VERSION ""

NS_ :

BS_:

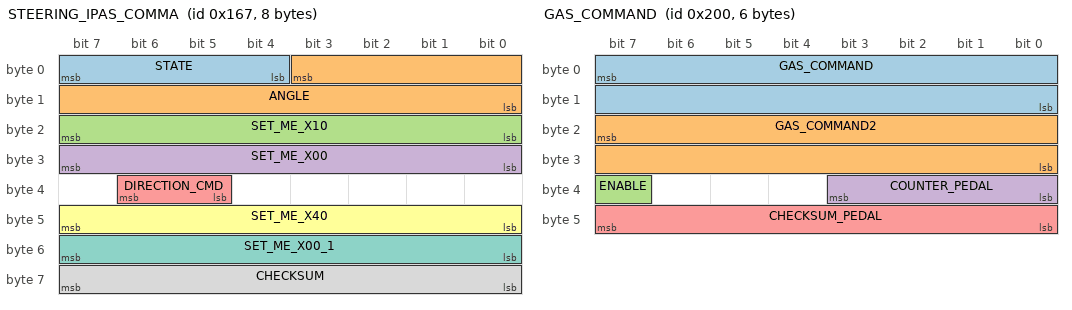
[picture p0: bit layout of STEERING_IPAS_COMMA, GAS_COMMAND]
BO_ 359 STEERING_IPAS_COMMA: 8 IPAS
 SG_ STATE : 7|4@0+ (1,0) [0|15] "" XXX
 SG_ ANGLE : 3|12@0- (1.5,0) [-510|510] "deg" XXX
 SG_ SET_ME_X10 : 23|8@0+ (1,0) [0|255] "" XXX
 SG_ SET_ME_X00 : 31|8@0+ (1,0) [0|255] "" XXX
 SG_ DIRECTION_CMD : 38|2@0+ (1,0) [0|3] "" XXX
 SG_ SET_ME_X40 : 47|8@0+ (1,0) [0|255] "" XXX
 SG_ SET_ME_X00_1 : 55|8@0+ (1,0) [0|255] "" XXX
 SG_ CHECKSUM : 63|8@0+ (1,0) [0|255] "" XXX

BO_ 512 GAS_COMMAND: 6 EON
 SG_ GAS_COMMAND : 7|16@0+ (0.159375,-75.555) [0|1] "" INTERCEPTOR
 SG_ GAS_COMMAND2 : 23|16@0+ (0.159375,-151.111) [0|1] "" INTERCEPTOR
 SG_ ENABLE : 39|1@0+ (1,0) [0|1] "" INTERCEPTOR
 SG_ COUNTER_PEDAL : 35|4@0+ (1,0) [0|15] "" INTERCEPTOR
 SG_ CHECKSUM_PEDAL : 47|8@0+ (1,0) [0|255] "" INTERCEPTOR

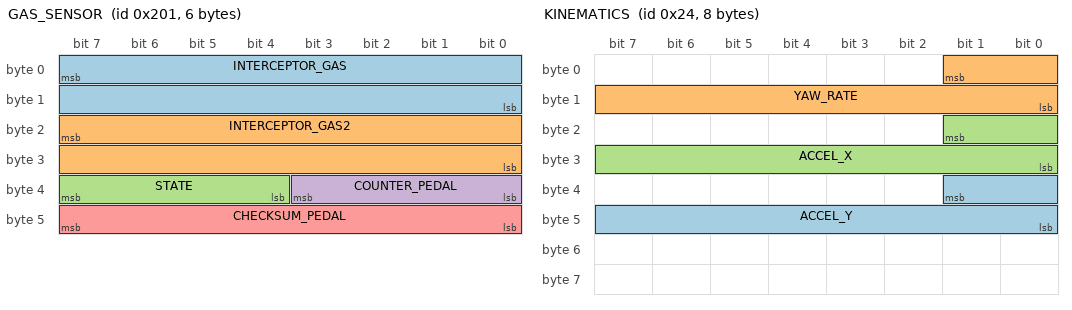
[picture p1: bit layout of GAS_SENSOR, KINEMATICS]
BO_ 513 GAS_SENSOR: 6 INTERCEPTOR
 SG_ INTERCEPTOR_GAS : 7|16@0+ (1,0) [0|1] "" EON
 SG_ INTERCEPTOR_GAS2 : 23|16@0+ (1,0) [0|1] "" EON
 SG_ STATE : 39|4@0+ (1,0) [0|15] "" EON
 SG_ COUNTER_PEDAL : 35|4@0+ (1,0) [0|15] "" EON
 SG_ CHECKSUM_PEDAL : 47|8@0+ (1,0) [0|255] "" EON

BO_ 35 SECONDARY_STEER_ANGLE: 8 XXX
 SG_ ZORRO_STEER : 7|24@0- (0.004901594652,0) [-500|500] "" XXX

BO_ 767 SDSU: 8 XXX
 SG_ FD_BUTTON : 7|1@0+ (1,0) [0|1] "" XXX

BO_ 36 KINEMATICS: 8 XXX
 SG_ ACCEL_Y : 33|10@0+ (0.03589,-18.375) [0|65535] "m/s^2" XXX
 SG_ YAW_RATE : 1|10@0+ (0.244,-125) [0|65535] "deg/s" XXX
 SG_ ACCEL_X : 17|10@0+ (0.03589,-18.375) [0|65535] "m/s^2" XXX

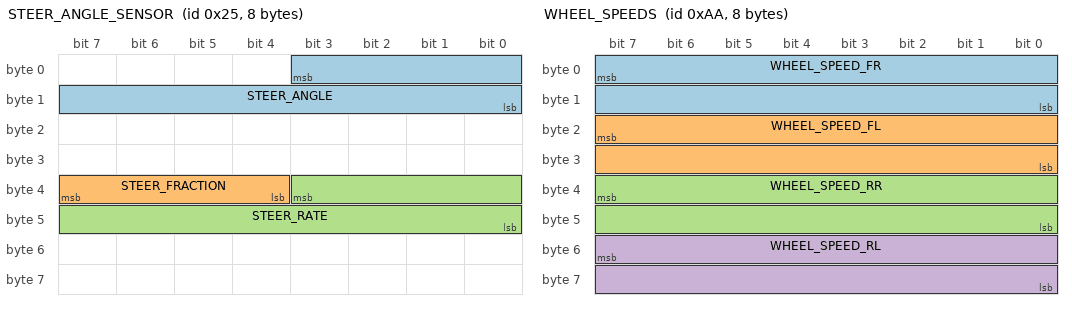
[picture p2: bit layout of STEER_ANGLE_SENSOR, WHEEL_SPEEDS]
BO_ 37 STEER_ANGLE_SENSOR: 8 XXX
 SG_ STEER_ANGLE : 3|12@0- (1.5,0) [-500|500] "deg" XXX
 SG_ STEER_FRACTION : 39|4@0- (0.1,0) [-0.7|0.7] "deg" XXX
 SG_ STEER_RATE : 35|12@0- (1,0) [-2000|2000] "deg/s" XXX

BO_ 166 BRAKE: 8 XXX
 SG_ BRAKE_AMOUNT : 7|8@0+ (1,0) [0|255] "" XXX
 SG_ BRAKE_PEDAL : 23|8@0+ (1,0) [0|255] "" XXX

BO_ 170 WHEEL_SPEEDS: 8 XXX
 SG_ WHEEL_SPEED_FR : 7|16@0+ (0.01,-67.67) [0|250] "km/h" XXX
 SG_ WHEEL_SPEED_FL : 23|16@0+ (0.01,-67.67) [0|250] "km/h" XXX
 SG_ WHEEL_SPEED_RR : 39|16@0+ (0.01,-67.67) [0|250] "km/h" XXX
 SG_ WHEEL_SPEED_RL : 55|16@0+ (0.01,-67.67) [0|250] "km/h" XXX

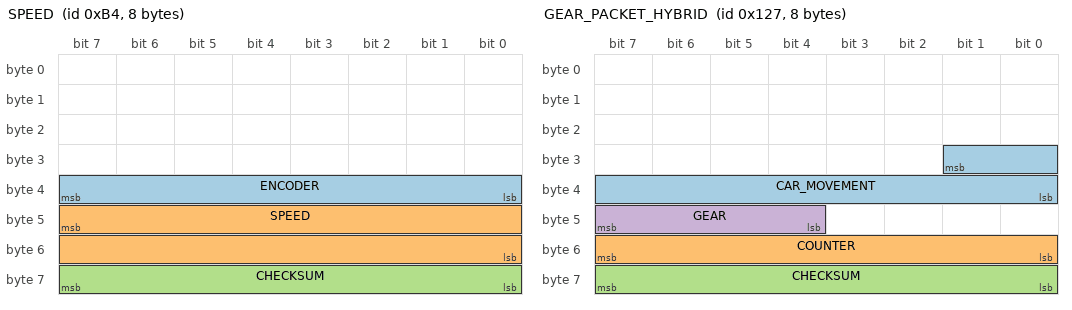
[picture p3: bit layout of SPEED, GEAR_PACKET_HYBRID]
BO_ 180 SPEED: 8 XXX
 SG_ ENCODER : 39|8@0+ (1,0) [0|255] "" XXX
 SG_ SPEED : 47|16@0+ (0.01,0) [0|250] "km/h" XXX
 SG_ CHECKSUM : 63|8@0+ (1,0) [0|255] "" XXX

BO_ 295 GEAR_PACKET_HYBRID: 8 XXX
 SG_ CAR_MOVEMENT : 25|10@0- (1,0) [0|255] "" XXX
 SG_ COUNTER : 55|8@0+ (1,0) [0|255] "" XXX
 SG_ CHECKSUM : 63|8@0+ (1,0) [0|255] "" XXX
 SG_ GEAR : 47|4@0+ (1,0) [0|15] "" XXX

BO_ 353 DSU_SPEED: 7 XXX
 SG_ FORWARD_SPEED : 15|16@0- (0.00390625,-30) [0|255] "km/h" XXX

BO_ 452 ENGINE_RPM: 8 CGW
 SG_ RPM : 7|16@0- (0.78125,0) [0|0] "rpm" SCS

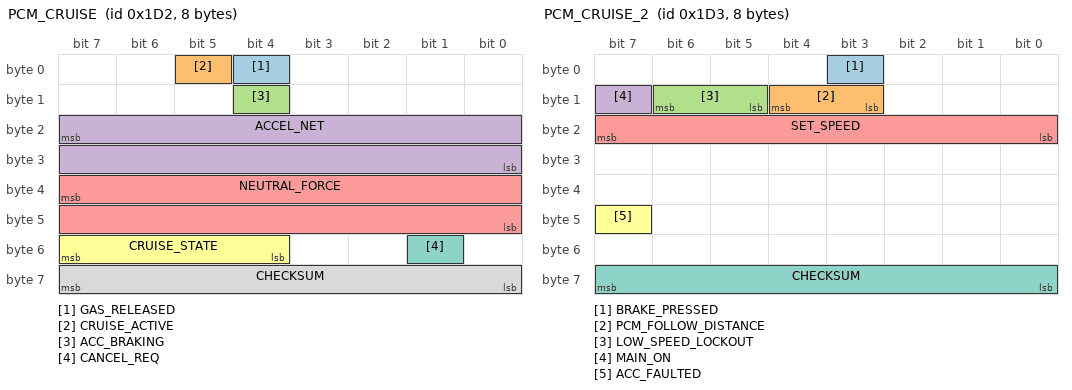
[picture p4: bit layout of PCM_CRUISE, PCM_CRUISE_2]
BO_ 466 PCM_CRUISE: 8 XXX
 SG_ GAS_RELEASED : 4|1@0+ (1,0) [0|1] "" XXX
 SG_ CRUISE_ACTIVE : 5|1@0+ (1,0) [0|1] "" XXX
 SG_ ACC_BRAKING : 12|1@0+ (1,0) [0|1] "" XXX
 SG_ ACCEL_NET : 23|16@0- (0.0009765625,0) [-20|20] "m/s^2" XXX
 SG_ NEUTRAL_FORCE : 39|16@0- (2,0) [-65536|65534] "N" XXX
 SG_ CRUISE_STATE : 55|4@0+ (1,0) [0|15] "" XXX
 SG_ CANCEL_REQ : 49|1@1+ (1,0) [0|1] "" XXX
 SG_ CHECKSUM : 63|8@0+ (1,0) [0|255] "" XXX

BO_ 467 PCM_CRUISE_2: 8 XXX
 SG_ BRAKE_PRESSED : 3|1@0+ (1,0) [0|1] "" XXX
 SG_ PCM_FOLLOW_DISTANCE : 12|2@0+ (1,0) [0|3] "" XXX
 SG_ LOW_SPEED_LOCKOUT : 14|2@0+ (1,0) [0|3] "" XXX
 SG_ MAIN_ON : 15|1@0+ (1,0) [0|1] "" XXX
 SG_ SET_SPEED : 23|8@0+ (1,0) [0|255] "km/h" XXX
 SG_ ACC_FAULTED : 47|1@0+ (1,0) [0|1] "" XXX
 SG_ CHECKSUM : 63|8@0+ (1,0) [0|255] "" XXX

BO_ 552 ACCELEROMETER: 8 XXX
 SG_ ACCEL_Z : 22|15@0- (1,0) [0|32767] "m/s^2" XXX
 SG_ ACCEL_X : 6|15@0- (0.001,0) [-20|20] "m/s^2" XXX

BO_ 560 BRAKE_2: 7 XXX
 SG_ BRAKE_PRESSED : 26|1@0+ (1,0) [0|1] "" XXX

BO_ 581 GAS_PEDAL_HYBRID: 8 XXX
 SG_ GAS_PEDAL : 23|8@0+ (0.005,0) [0|1] "" XXX

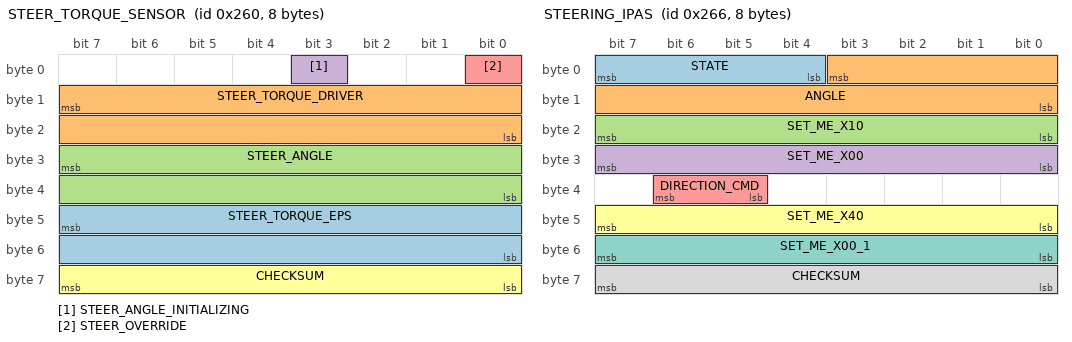
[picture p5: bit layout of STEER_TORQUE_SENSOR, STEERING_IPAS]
BO_ 608 STEER_TORQUE_SENSOR: 8 XXX
 SG_ STEER_TORQUE_EPS : 47|16@0- (1,0) [-32768|32767] "" XXX
 SG_ STEER_TORQUE_DRIVER : 15|16@0- (1,0) [-32768|32767] "" XXX
 SG_ STEER_ANGLE : 31|16@0- (0.0573,0) [-500|500] "" XXX
 SG_ STEER_ANGLE_INITIALIZING : 3|1@0+ (1,0) [0|1] "" XXX
 SG_ STEER_OVERRIDE : 0|1@0+ (1,0) [0|1] "" XXX
 SG_ CHECKSUM : 63|8@0+ (1,0) [0|255] "" XXX

BO_ 614 STEERING_IPAS: 8 IPAS
 SG_ STATE : 7|4@0+ (1,0) [0|15] "" XXX
 SG_ ANGLE : 3|12@0- (1.5,0) [-510|510] "deg" XXX
 SG_ SET_ME_X10 : 23|8@0+ (1,0) [0|255] "" XXX
 SG_ SET_ME_X00 : 31|8@0+ (1,0) [0|255] "" XXX
 SG_ DIRECTION_CMD : 38|2@0+ (1,0) [0|3] "" XXX
 SG_ SET_ME_X40 : 47|8@0+ (1,0) [0|255] "" XXX
 SG_ SET_ME_X00_1 : 55|8@0+ (1,0) [0|255] "" XXX
 SG_ CHECKSUM : 63|8@0+ (1,0) [0|255] "" XXX

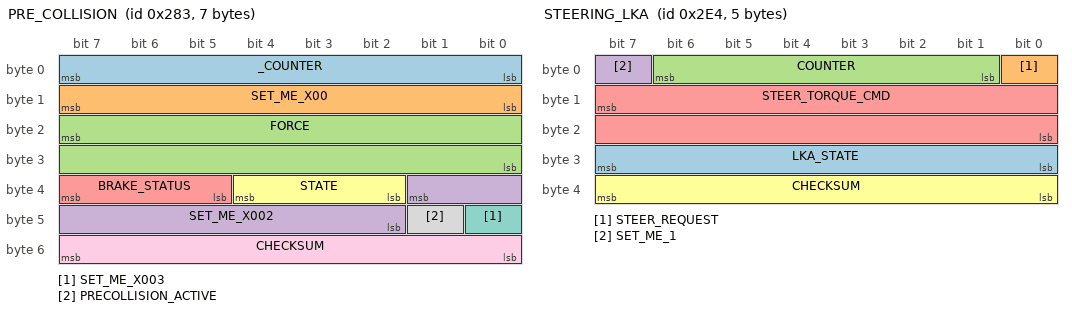
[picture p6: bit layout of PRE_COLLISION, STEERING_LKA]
BO_ 643 PRE_COLLISION: 7 DSU
 SG_ _COUNTER : 7|8@0+ (1,0) [0|255] "" XXX
 SG_ SET_ME_X00 : 15|8@0+ (1,0) [0|255] "" XXX
 SG_ FORCE : 23|16@0- (2,0) [0|255] "N" XXX
 SG_ SET_ME_X002 : 33|8@0+ (1,0) [0|3] "" XXX
 SG_ BRAKE_STATUS : 39|3@0+ (1,0) [0|255] "" XXX
 SG_ STATE : 36|3@0+ (1,0) [0|255] "" XXX
 SG_ SET_ME_X003 : 40|1@0+ (1,0) [0|1] "" XXX
 SG_ PRECOLLISION_ACTIVE : 41|1@0+ (1,0) [0|255] "" XXX
 SG_ CHECKSUM : 55|8@0+ (1,0) [0|255] "" XXX

BO_ 705 GAS_PEDAL: 8 XXX
 SG_ GAS_RELEASED : 3|1@0+ (1,0) [0|1] "" XXX
 SG_ GAS_PEDAL : 55|8@0+ (0.005,0) [0|1] "" XXX

BO_ 740 STEERING_LKA: 5 XXX
 SG_ LKA_STATE : 31|8@0+ (1,0) [0|255] "" XXX
 SG_ STEER_REQUEST : 0|1@0+ (1,0) [0|1] "" XXX
 SG_ COUNTER : 6|6@0+ (1,0) [0|63] "" XXX
 SG_ SET_ME_1 : 7|1@0+ (1,0) [0|1] "" XXX
 SG_ STEER_TORQUE_CMD : 15|16@0- (1,0) [0|65535] "" XXX
 SG_ CHECKSUM : 39|8@0+ (1,0) [0|255] "" XXX

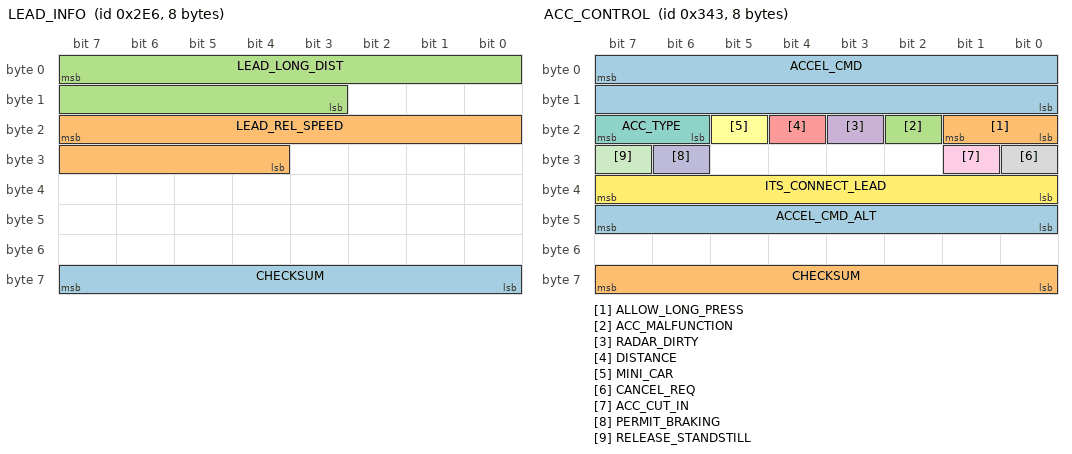
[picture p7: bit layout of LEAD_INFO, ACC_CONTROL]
BO_ 742 LEAD_INFO: 8 DSU
 SG_ CHECKSUM : 63|8@0+ (1,0) [0|255] "" HCU
 SG_ LEAD_REL_SPEED : 23|12@0- (0.025,0) [-100|100] "m/s" HCU
 SG_ LEAD_LONG_DIST : 7|13@0+ (0.05,0) [0|300] "m" HCU

BO_ 835 ACC_CONTROL: 8 DSU
 SG_ ACCEL_CMD : 7|16@0- (0.001,0) [-20|20] "m/s^2" HCU
 SG_ ALLOW_LONG_PRESS : 17|2@0+ (1,0) [0|2] "" XXX
 SG_ ACC_MALFUNCTION : 18|1@0+ (1,0) [0|0] "" XXX
 SG_ RADAR_DIRTY : 19|1@0+ (1,0) [0|1] "" XXX
 SG_ DISTANCE : 20|1@0+ (1,0) [0|1] "" XXX
 SG_ MINI_CAR : 21|1@0+ (1,0) [0|1] "" XXX
 SG_ ACC_TYPE : 23|2@0+ (1,0) [0|3] "" HCU
 SG_ CANCEL_REQ : 24|1@0+ (1,0) [0|1] "" HCU
 SG_ ACC_CUT_IN : 25|1@0+ (1,0) [0|1] "" XXX
 SG_ PERMIT_BRAKING : 30|1@0+ (1,0) [0|1] "" HCU
 SG_ RELEASE_STANDSTILL : 31|1@0+ (1,0) [0|1] "" HCU
 SG_ ITS_CONNECT_LEAD : 39|8@0+ (1,0) [0|1] "" Vector__XXX
 SG_ ACCEL_CMD_ALT : 47|8@0- (0.05,0) [0|0] "m/s^2" XXX
 SG_ CHECKSUM : 63|8@0+ (1,0) [0|255] "" XXX

BO_ 836 PRE_COLLISION_2: 8 DSU
 SG_ CHECKSUM : 63|8@0+ (1,0) [0|0] "" XXX

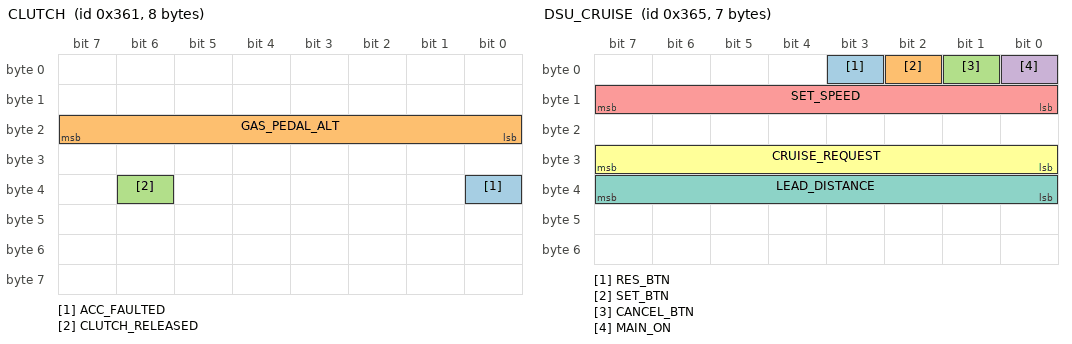
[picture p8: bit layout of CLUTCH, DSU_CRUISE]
BO_ 865 CLUTCH: 8 XXX
 SG_ ACC_FAULTED : 32|1@0+ (1,0) [0|1] "" XXX
 SG_ GAS_PEDAL_ALT : 23|8@0+ (0.005,0) [0|1] "" XXX
 SG_ CLUTCH_RELEASED : 38|1@0+ (1,0) [0|1] "" XXX

BO_ 869 DSU_CRUISE : 7 DSU
 SG_ RES_BTN : 3|1@0+ (1,0) [0|0] "" XXX
 SG_ SET_BTN : 2|1@0+ (1,0) [0|0] "" XXX
 SG_ CANCEL_BTN : 1|1@0+ (1,0) [0|0] "" XXX
 SG_ MAIN_ON : 0|1@0+ (1,0) [0|0] "" XXX
 SG_ SET_SPEED : 15|8@0+ (1,0) [0|0] "km/h" XXX
 SG_ CRUISE_REQUEST : 31|8@0+ (100,-12800) [0|0] "N" XXX
 SG_ LEAD_DISTANCE : 39|8@0+ (1,0) [0|0] "m" XXX

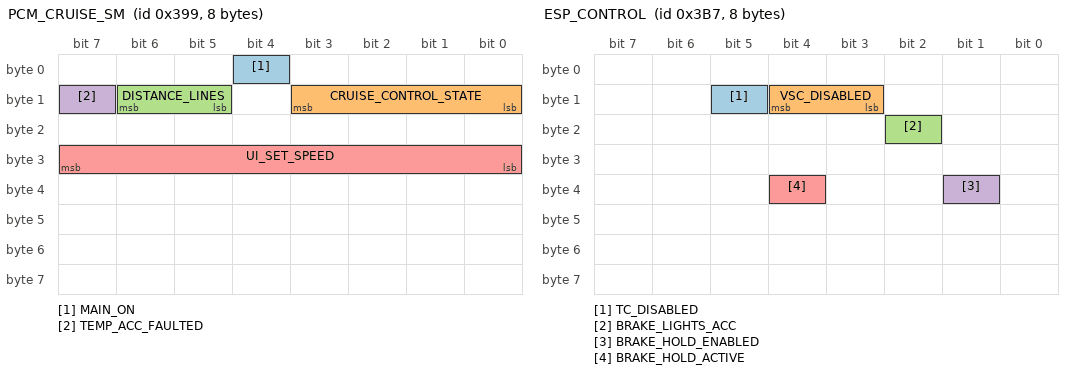
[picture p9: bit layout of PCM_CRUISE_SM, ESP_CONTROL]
BO_ 921 PCM_CRUISE_SM: 8 XXX
 SG_ MAIN_ON : 4|1@0+ (1,0) [0|1] "" XXX
 SG_ CRUISE_CONTROL_STATE : 11|4@0+ (1,0) [0|15] "" XXX
 SG_ DISTANCE_LINES : 14|2@0+ (1,0) [0|3] "" XXX
 SG_ TEMP_ACC_FAULTED : 15|1@0+ (1,0) [0|1] "" XXX
 SG_ UI_SET_SPEED : 31|8@0+ (1,0) [0|255] "" XXX

BO_ 951 ESP_CONTROL: 8 ESP
 SG_ TC_DISABLED : 13|1@0+ (1,0) [0|1] "" XXX
 SG_ VSC_DISABLED : 12|2@0+ (1,0) [0|1] "" XXX
 SG_ BRAKE_LIGHTS_ACC : 18|1@0+ (1,0) [0|1] "" XXX
 SG_ BRAKE_HOLD_ENABLED : 33|1@1+ (1,0) [0|1] "" XXX
 SG_ BRAKE_HOLD_ACTIVE : 36|1@0+ (1,0) [0|1] "" XXX

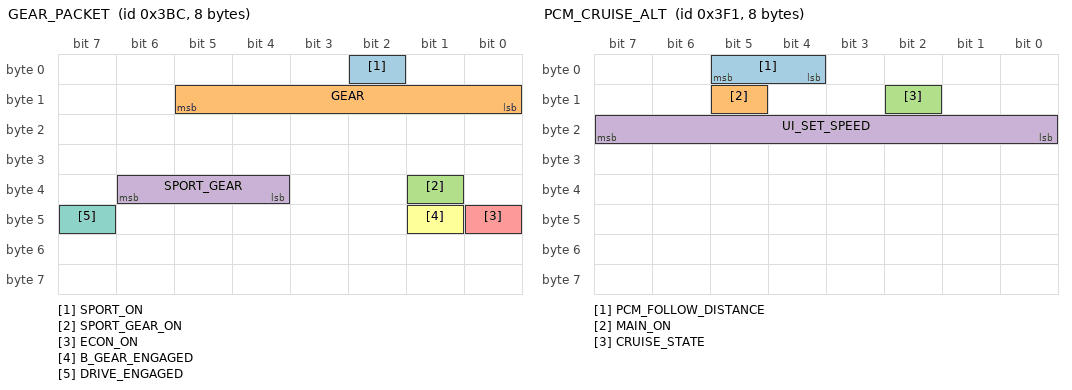
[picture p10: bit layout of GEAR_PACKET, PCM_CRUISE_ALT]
BO_ 956 GEAR_PACKET: 8 XXX
 SG_ SPORT_ON : 2|1@0+ (1,0) [0|1] "" XXX
 SG_ GEAR : 13|6@0+ (1,0) [0|63] "" XXX
 SG_ SPORT_GEAR_ON : 33|1@0+ (1,0) [0|1] "" XXX
 SG_ SPORT_GEAR : 38|3@0+ (1,0) [0|7] "" XXX
 SG_ ECON_ON : 40|1@0+ (1,0) [0|1] "" XXX
 SG_ B_GEAR_ENGAGED : 41|1@0+ (1,0) [0|1] "" XXX
 SG_ DRIVE_ENGAGED : 47|1@0+ (1,0) [0|1] "" XXX

BO_ 1005 REVERSE_CAMERA_STATE: 2 BGM
 SG_ REVERSE_CAMERA_GUIDELINES : 9|2@0+ (1,0) [1|3] "" XXX

BO_ 1009 PCM_CRUISE_ALT: 8 XXX
 SG_ PCM_FOLLOW_DISTANCE : 4|2@1+ (1,0) [0|3] "" XXX
 SG_ MAIN_ON : 13|1@0+ (1,0) [0|3] "" XXX
 SG_ CRUISE_STATE : 10|1@0+ (1,0) [0|1] "" XXX
 SG_ UI_SET_SPEED : 23|8@0+ (1,0) [0|255] "mph" XXX

BO_ 1020 SOLAR_SENSOR: 8 XXX
 SG_ LUX_SENSOR : 55|13@0+ (1,0) [0|0] "" XXX

BO_ 1041 PCS_HUD: 8 DSU
 SG_ PCS_INDICATOR : 7|2@0+ (1,0) [0|3] "" XXX
 SG_ FCW : 4|1@0+ (1,0) [0|1] "" XXX
 SG_ SET_ME_X20 : 15|8@0+ (1,0) [0|1] "" XXX
 SG_ PCS_DUST : 34|1@0+ (1,0) [0|0] "" XXX
 SG_ PCS_TEMP : 35|1@0+ (1,0) [0|0] "" XXX
 SG_ PCS_DUST2 : 41|1@0+ (1,0) [0|0] "" XXX
 SG_ PCS_TEMP2 : 42|1@0+ (1,0) [0|0] "" XXX
 SG_ SET_ME_X10 : 39|8@0+ (1,0) [0|1] "" XXX
 SG_ PCS_OFF : 40|1@0+ (1,0) [0|0] "" XXX
 SG_ FRD_ADJ : 53|3@0+ (1,0) [0|0] "" XXX
 SG_ PCS_SENSITIVITY : 55|8@0+ (1,0) [0|1] "" XXX

BO_ 1042 LKAS_HUD: 8 DSU
 SG_ BARRIERS : 1|2@0+ (1,0) [0|3] "" XXX
 SG_ RIGHT_LINE : 3|2@0+ (1,0) [0|3] "" XXX
 SG_ LEFT_LINE : 5|2@0+ (1,0) [0|3] "" XXX
 SG_ LKAS_STATUS : 7|2@0+ (1,0) [0|3] "" XXX
 SG_ LDA_ALERT : 9|2@0+ (1,0) [0|3] "" XXX
 SG_ LDW_EXIST : 10|1@0+ (1,0) [0|1] "" XXX
 SG_ TWO_BEEPS : 12|1@0+ (1,0) [0|1] "" XXX
 SG_ ADJUSTING_CAMERA : 13|1@0+ (1,0) [0|1] "" XXX
 SG_ LDA_UNAVAILABLE_QUIET : 14|1@0+ (1,0) [0|1] "" XXX
 SG_ LDA_MALFUNCTION : 15|1@0+ (1,0) [0|1] "" XXX
 SG_ LDA_UNAVAILABLE : 16|1@0+ (1,0) [0|1] "" XXX
 SG_ LDA_SENSITIVITY : 18|2@0+ (1,0) [0|3] "" XXX
 SG_ LDA_SA_TOGGLE : 20|2@0+ (1,0) [0|3] "" XXX
 SG_ LDA_MESSAGES : 23|3@0+ (1,0) [0|1] "" XXX
 SG_ LDA_ON_MESSAGE : 31|2@0+ (1,0) [0|3] "" XXX
 SG_ REPEATED_BEEPS : 32|1@0+ (1,0) [0|1] "" XXX
 SG_ LANE_SWAY_TOGGLE : 43|1@0+ (1,0) [0|1] "" XXX
 SG_ LANE_SWAY_SENSITIVITY : 45|2@0+ (1,0) [0|3] "" XXX
 SG_ TAKE_CONTROL : 46|1@0+ (1,0) [0|1] "" XXX
 SG_ LDA_FRONT_CAMERA_BLOCKED : 47|1@0+ (1,0) [0|1] "" XXX
 SG_ LANE_SWAY_BUZZER : 50|2@0+ (1,0) [0|0] "" XXX
 SG_ LANE_SWAY_FLD : 53|3@0+ (1,0) [0|7] "" XXX
 SG_ LANE_SWAY_WARNING : 55|2@0+ (1,0) [0|3] "" XXX
 SG_ SET_ME_X01 : 42|1@0+ (1,0) [0|1] "" XXX
 SG_ SET_ME_X02 : 63|8@0+ (1,0) [0|1] "" XXX

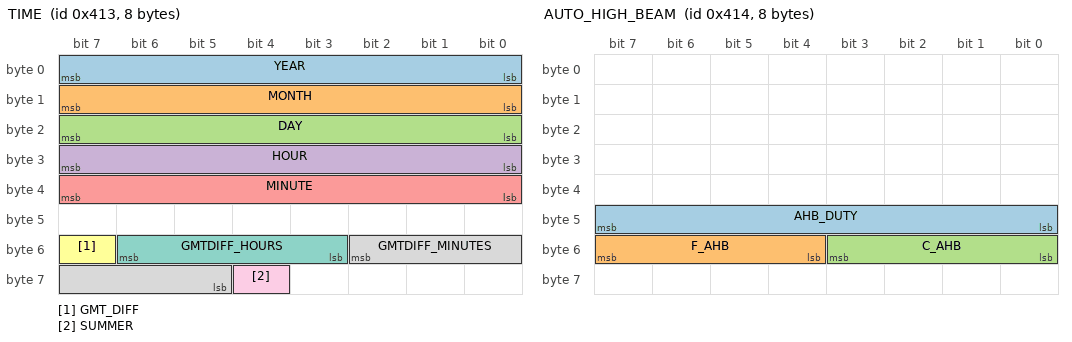
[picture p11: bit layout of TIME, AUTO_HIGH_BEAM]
BO_ 1043 TIME : 8 CGW
 SG_ YEAR : 7|8@0+ (1,0) [0|0] "year" XXX
 SG_ MONTH : 15|8@0+ (1,0) [0|0] "month" XXX
 SG_ DAY : 23|8@0+ (1,0) [0|0] "day" XXX
 SG_ HOUR : 31|8@0+ (1,0) [0|0] "hour" XXX
 SG_ MINUTE : 39|8@0+ (1,0) [0|0] "minute" XXX
 SG_ GMT_DIFF : 55|1@0+ (1,0) [0|0] "" XXX
 SG_ GMTDIFF_HOURS : 54|4@0+ (1,0) [0|0] "hours" XXX
 SG_ GMTDIFF_MINUTES : 50|6@0+ (1,0) [0|0] "minutes" XXX
 SG_ SUMMER : 60|1@0+ (1,0) [0|0] "" XXX

BO_ 1044 AUTO_HIGH_BEAM: 8 FCM
 SG_ AHB_DUTY : 47|8@0+ (0.5,0) [0|0] "%" Vector__XXX
 SG_ F_AHB : 55|4@0+ (1,0) [0|0] "" Vector__XXX
 SG_ C_AHB : 51|4@0+ (1,0) [0|0] "" Vector__XXX

BO_ 1083 AUTOPARK_STATUS: 8 IPAS
 SG_ STATE : 7|4@0+ (1,0) [0|15] "" XXX

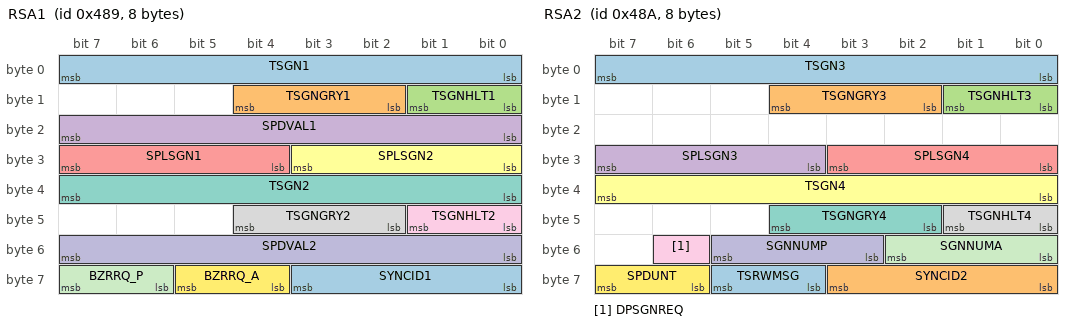
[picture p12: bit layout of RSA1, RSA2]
BO_ 1161 RSA1: 8 FCM
 SG_ TSGN1 : 7|8@0+ (1,0) [0|0] "" XXX
 SG_ TSGNGRY1 : 12|3@0+ (1,0) [0|0] "" XXX
 SG_ TSGNHLT1 : 9|2@0+ (1,0) [0|0] "" XXX
 SG_ SPDVAL1 : 23|8@0+ (1,0) [0|0] "km/h" XXX
 SG_ SPLSGN1 : 31|4@0+ (1,0) [0|0] "" XXX
 SG_ SPLSGN2 : 27|4@0+ (1,0) [0|0] "" XXX
 SG_ TSGN2 : 39|8@0+ (1,0) [0|0] "" XXX
 SG_ TSGNGRY2 : 44|3@0+ (1,0) [0|0] "" XXX
 SG_ TSGNHLT2 : 41|2@0+ (1,0) [0|0] "" XXX
 SG_ SPDVAL2 : 55|8@0+ (1,0) [0|0] "" XXX
 SG_ BZRRQ_P : 63|2@0+ (1,0) [0|0] "" XXX
 SG_ BZRRQ_A : 61|2@0+ (1,0) [0|0] "" XXX
 SG_ SYNCID1 : 59|4@0+ (1,0) [0|0] "" XXX

BO_ 1162 RSA2: 8 FCM
 SG_ TSGN3 : 7|8@0+ (1,0) [0|0] "" XXX
 SG_ TSGNGRY3 : 12|3@0+ (1,0) [0|0] "" XXX
 SG_ TSGNHLT3 : 9|2@0+ (1,0) [0|0] "" XXX
 SG_ SPLSGN3 : 31|4@0+ (1,0) [0|0] "" XXX
 SG_ SPLSGN4 : 27|4@0+ (1,0) [0|0] "" XXX
 SG_ TSGN4 : 39|8@0+ (1,0) [0|0] "" XXX
 SG_ TSGNGRY4 : 44|3@0+ (1,0) [0|0] "" XXX
 SG_ TSGNHLT4 : 41|2@0+ (1,0) [0|0] "" XXX
 SG_ DPSGNREQ : 54|1@0+ (1,0) [0|0] "" XXX
 SG_ SGNNUMP : 53|3@0+ (1,0) [0|0] "" XXX
 SG_ SGNNUMA : 50|3@0+ (1,0) [0|0] "" XXX
 SG_ SPDUNT : 63|2@0+ (1,0) [0|0] "" XXX
 SG_ TSRWMSG : 61|2@0+ (1,0) [0|0] "" XXX
 SG_ SYNCID2 : 59|4@0+ (1,0) [0|0] "" XXX

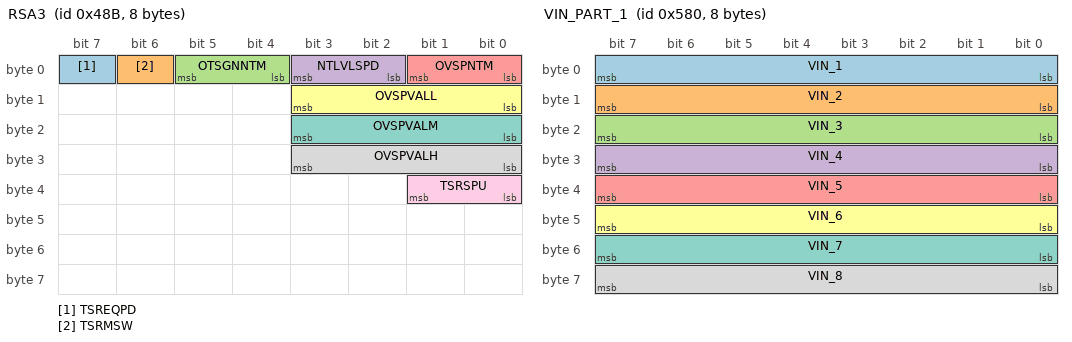
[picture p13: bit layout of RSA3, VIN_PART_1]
BO_ 1163 RSA3: 8 FCM
 SG_ TSREQPD : 7|1@0+ (1,0) [0|0] "" XXX
 SG_ TSRMSW : 6|1@0+ (1,0) [0|0] "" XXX
 SG_ OTSGNNTM : 5|2@0+ (1,0) [0|0] "" XXX
 SG_ NTLVLSPD : 3|2@0+ (1,0) [0|0] "" XXX
 SG_ OVSPNTM : 1|2@0+ (1,0) [0|0] "" XXX
 SG_ OVSPVALL : 11|4@0+ (1,-5) [0|0] "" XXX
 SG_ OVSPVALM : 19|4@0+ (1,-5) [0|0] "" XXX
 SG_ OVSPVALH : 27|4@0+ (1,-5) [0|0] "" XXX
 SG_ TSRSPU : 33|2@0+ (1,0) [0|0] "" XXX

BO_ 1408 VIN_PART_1: 8 CGW
 SG_ VIN_1 : 7|8@0+ (1,0) [0|0] "" XXX
 SG_ VIN_2 : 15|8@0+ (1,0) [0|0] "" XXX
 SG_ VIN_3 : 23|8@0+ (1,0) [0|0] "" XXX
 SG_ VIN_4 : 31|8@0+ (1,0) [0|0] "" XXX
 SG_ VIN_5 : 39|8@0+ (1,0) [0|0] "" XXX
 SG_ VIN_6 : 47|8@0+ (1,0) [0|0] "" XXX
 SG_ VIN_7 : 55|8@0+ (1,0) [0|0] "" XXX
 SG_ VIN_8 : 63|8@0+ (1,0) [0|0] "" XXX

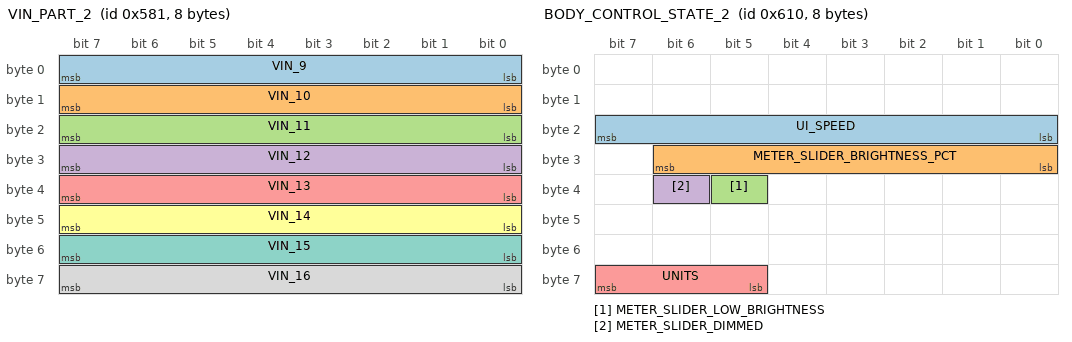
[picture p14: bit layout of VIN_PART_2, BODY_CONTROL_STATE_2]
BO_ 1409 VIN_PART_2: 8 CGW
 SG_ VIN_9 : 7|8@0+ (1,0) [0|0] "" XXX
 SG_ VIN_10 : 15|8@0+ (1,0) [0|0] "" XXX
 SG_ VIN_11 : 23|8@0+ (1,0) [0|0] "" XXX
 SG_ VIN_12 : 31|8@0+ (1,0) [0|0] "" XXX
 SG_ VIN_13 : 39|8@0+ (1,0) [0|0] "" XXX
 SG_ VIN_14 : 47|8@0+ (1,0) [0|0] "" XXX
 SG_ VIN_15 : 55|8@0+ (1,0) [0|0] "" XXX
 SG_ VIN_16 : 63|8@0+ (1,0) [0|0] "" XXX

BO_ 1410 VIN_PART_3: 8 CGW
 SG_ VIN_17 : 7|8@0+ (1,0) [0|0] "" XXX

BO_ 1552 BODY_CONTROL_STATE_2: 8 XXX
 SG_ UI_SPEED : 23|8@0+ (1,0) [0|255] "" XXX
 SG_ METER_SLIDER_BRIGHTNESS_PCT : 30|7@0+ (1,0) [12|100] "%" XXX
 SG_ METER_SLIDER_LOW_BRIGHTNESS : 37|1@0+ (1,0) [0|1] "" XXX
 SG_ METER_SLIDER_DIMMED : 38|1@0+ (1,0) [0|1] "" XXX
 SG_ UNITS : 63|3@0+ (1,0) [1|4] "" XXX

BO_ 1553 UI_SETTING: 8 XXX
 SG_ UNITS : 26|2@0+ (1,0) [0|3] "" XXX
 SG_ ODOMETER : 39|32@0+ (1,0) [0|1048575] "" XXX
BO_ 1556 BLINKERS_STATE: 8 XXX
 SG_ TURN_SIGNALS : 29|2@0+ (1,0) [0|3] "" XXX
 SG_ HAZARD_LIGHT : 27|1@0+ (1,0) [0|1] "" XXX

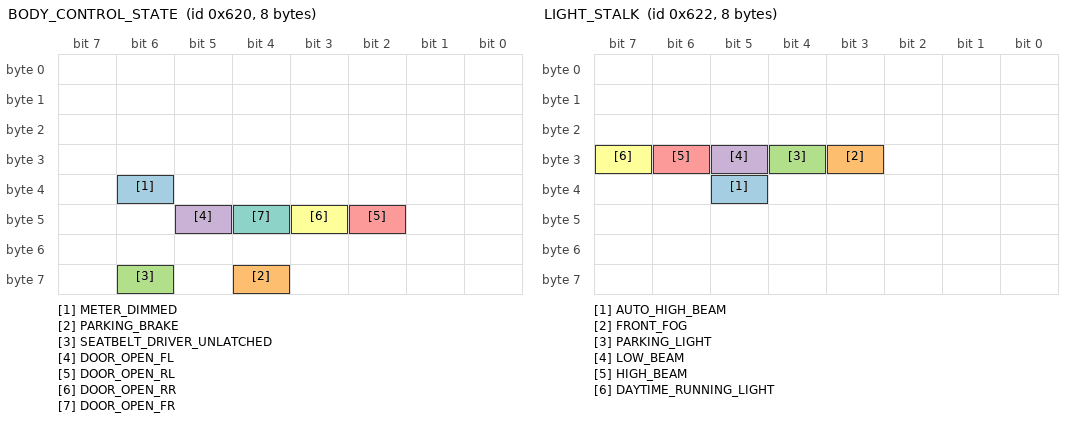
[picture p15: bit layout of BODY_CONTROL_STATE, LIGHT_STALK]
BO_ 1568 BODY_CONTROL_STATE: 8 XXX
 SG_ METER_DIMMED : 38|1@0+ (1,0) [0|1] "" XXX
 SG_ PARKING_BRAKE : 60|1@0+ (1,0) [0|1] "" XXX
 SG_ SEATBELT_DRIVER_UNLATCHED : 62|1@0+ (1,0) [0|1] "" XXX
 SG_ DOOR_OPEN_FL : 45|1@0+ (1,0) [0|1] "" XXX
 SG_ DOOR_OPEN_RL : 42|1@0+ (1,0) [0|1] "" XXX
 SG_ DOOR_OPEN_RR : 43|1@0+ (1,0) [0|1] "" XXX
 SG_ DOOR_OPEN_FR : 44|1@0+ (1,0) [0|1] "" XXX

BO_ 1570 LIGHT_STALK: 8 SCM
 SG_ AUTO_HIGH_BEAM : 37|1@0+ (1,0) [0|1] "" XXX
 SG_ FRONT_FOG : 27|1@0+ (1,0) [0|1] "" XXX
 SG_ PARKING_LIGHT : 28|1@0+ (1,0) [0|1] "" XXX
 SG_ LOW_BEAM : 29|1@0+ (1,0) [0|1] "" XXX
 SG_ HIGH_BEAM : 30|1@0+ (1,0) [0|1] "" XXX
 SG_ DAYTIME_RUNNING_LIGHT : 31|1@0+ (1,0) [0|1] "" XXX

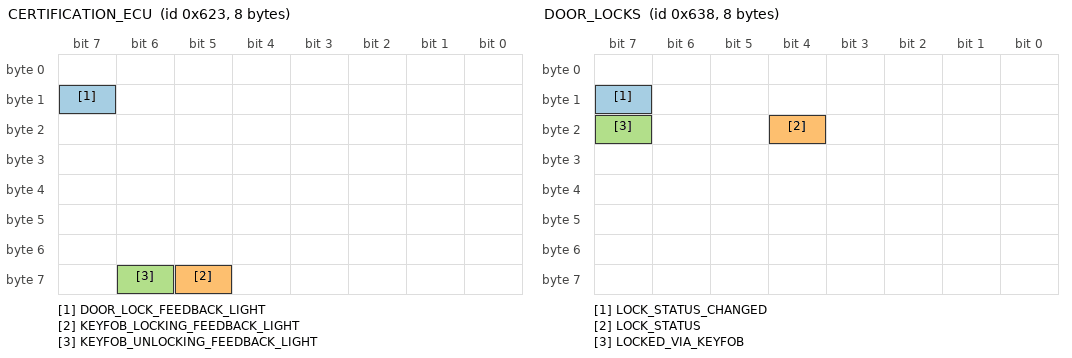
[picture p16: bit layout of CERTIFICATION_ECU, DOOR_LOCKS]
BO_ 1571 CERTIFICATION_ECU: 8 CGW
 SG_ DOOR_LOCK_FEEDBACK_LIGHT : 15|1@0+ (1,0) [0|0] "" XXX
 SG_ KEYFOB_LOCKING_FEEDBACK_LIGHT : 61|1@0+ (1,0) [0|0] "" XXX
 SG_ KEYFOB_UNLOCKING_FEEDBACK_LIGHT : 62|1@0+ (1,0) [0|0] "" XXX

BO_ 1592 DOOR_LOCKS: 8 XXX
 SG_ LOCK_STATUS_CHANGED : 15|1@0+ (1,0) [0|1] "" XXX
 SG_ LOCK_STATUS : 20|1@0+ (1,0) [0|1] "" XXX
 SG_ LOCKED_VIA_KEYFOB : 23|1@0+ (1,0) [0|1] "" XXX

BO_ 548 BRAKE_MODULE: 8 XXX
 SG_ BRAKE_PRESSURE : 43|12@0+ (1,0) [0|4047] "" XXX
 SG_ BRAKE_PRESSED : 5|1@0+ (1,0) [0|1] "" XXX

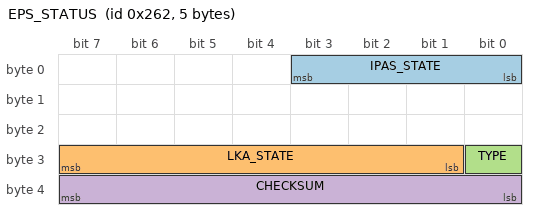
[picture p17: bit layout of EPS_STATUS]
BO_ 610 EPS_STATUS: 5 EPS
 SG_ IPAS_STATE : 3|4@0+ (1,0) [0|15] "" XXX
 SG_ LKA_STATE : 31|7@0+ (1,0) [0|127] "" XXX
 SG_ TYPE : 24|1@0+ (1,0) [0|1] "" XXX
 SG_ CHECKSUM : 39|8@0+ (1,0) [0|255] "" XXX

BO_ 1178 BRAKE_RELATED: 8 XXX
 SG_ BRAKE_PRESSED : 48|1@0+ (1,0) [0|1] "" XXX

BU_: RRSRR_FO LRSRR_FO CIPM_FO _DOFIMU2_FO _DOFIMU1_FO DMS_FO AMM_FO EOCM2B_IMX6_FO EOCM2B_K2_FO EOCM2B_K1_FO EOCM2A_IMX6_FO EOCM2A_K2_FO EOCM2A_K1_FO NVS_FO Dummy_FO TestTool_FO LRR_FO RFSRR_FO LFSRR_FO RSRR_FO VIS_FO EOCM_F_FO VIS2_FO
VAL_TABLE_ vt_BooleanValues 1 "true" 0 "false" ;
VAL_TABLE_ FrntVsnInPthVehBrkNwSt 10 "Active" 5 "Inactive" ;
VAL_TABLE_ FrntVsnClostPedBrkNwSt 10 "Active" 5 "Inactive" ;
VAL_TABLE_ DrvrMonSysEngSt 7 "Unused and Reserved 1" 6 "Recovering" 5 "Tracking" 4 "Searching" 3 "Video test port only" 2 "Idle" 1 "Invalid state" 0 "Does not exist or DME" ;
VAL_TABLE_ DrvrMonEngUnrecvrFltCod 7 "Unused and Reserved 3" 6 "Unused and Reserved 2" 5 "Unused and Reserved 1" 4 "Vehicle power supply Errors" 3 "Problem with LED illuminators" 2 "Vehicle input signals Errors" 1 "Problem with imager" 0 "Ok" ;
VAL_TABLE_ DrvrMonEngRecvrFltCod 3 "Engine is unable to find a face" 2 "Input Images too dark" 1 "Input images too bright" 0 "Ok" ;
VAL_TABLE_ DrvrMntrSysVTP 1 "Video test port active" 0 "Video test port inactive" ;
VAL_TABLE_ DrvrAttnStatCnfdc 3 "High" 2 "Medium" 1 "Low" 0 "Lowest" ;
VAL_TABLE_ DrvrAttnStat 7 "Invalid" 6 "Driver is exhibiting sleep" 5 "Driver is exhibiting microsleep" 4 "Attention is Center Console" 3 "Attention is Drivers Lap" 2 "Attention is Off Road" 1 "Attention is On Road" 0 "Unknown" ;
VAL_TABLE_ PPSMd 7 "GNSS and RTX and DR and MM" 6 "DR ONLY" 5 "GNSS and RTX and DR" 4 "GNSS and SBAS and DR" 3 "GNSS and DR" 2 "GNSS and  RTX" 1 "GNSS and SBAS" 0 "GNSS Standalone" ;
VAL_TABLE_ AdvDrvAstMpPrfShrtAcur 3 "Accuracy Is Unknown" 2 "Lowest Accuracy" 1 "Medium Accuracy" 0 "Highest Accuracy" ;
VAL_TABLE_ AdvDrAstMpStbRtOfWay 3 "Not Applicable" 2 "Unknown" 1 "Sub Path Has Right Of Way Over Path" 0 "Path Has Right Of Way Over Sub Path" ;
VAL_TABLE_ AdvDrAstMpStbPrtCalRut 3 "Not Applicable" 2 "Unknown" 1 "Path From This Point On Is Part Of Calculated Route" 0 "Path From This Point On Is Not Part Of Calculated Route" ;
VAL_TABLE_ AdvDrAstMpStbMsgTyp 7 "Unused and Reserved 2" 6 "Metadata" 5 "Profile Long" 4 "Profile Short" 3 "Stub" 2 "Segment" 1 "Position" 0 "Unused and Reserved 1" ;
VAL_TABLE_ AdvDrAstMpStbFmOfWay 15 "Not Applicable" 14 "Pedestrian Zone" 13 "Entrance To Or Exit To Service" 12 "Entrance To Or Exit Of A Car Park" 11 "Service Road Or Frontage Road" 10 "Slip Road per Ramp" 9 "Slip Road per Ramp On A Freeway Or Controlled Access Road" 8 "Parallel Road" 7 "Unused and Reserved 2" 6 "Unused and Reserved 1" 5 "Traffic Square per Special Traffic Figure" 4 "Roundabout Circle" 3 "Single Carriageway" 2 "Multiple Carriageway Or Multiply Digitized Road" 1 "Freeway Or Controlled Access Road That Is Not A Slip Road Or Ramp" 0 "Unknown" ;
VAL_TABLE_ AdvDrAstMpStbCmplxInsct 3 "Not Applicable" 2 "Unknown" 1 "Stub Is Part Of Complex Intersection" 0 "Stub Is Not Part Of Complex Intersection" ;
VAL_TABLE_ AdvDrAstMpSegTunl 3 "Not Applicable" 2 "Unknown" 1 "Segment Is Part Of Tunnel" 0 "Segment Is Not A Part Of Tunnel" ;
VAL_TABLE_ AdvDrAstMpSegPrtCalRut 3 "Not Applicable" 2 "Unknown" 1 "Segment Is Part Of Calculated Route" 0 "Segment Is Not Part Of Calculated Route" ;
VAL_TABLE_ AdvDrAstMpSegMsgTyp 7 "Unused and Reserved 2" 6 "Metadata" 5 "Profile Long" 4 "Profile Short" 3 "Stub" 2 "Segment" 1 "Position" 0 "Unused and Reserved 1" ;
VAL_TABLE_ AdvDrAstMpSegFrmOfWay 15 "Not Applicable" 14 "Pedestrian Zone" 13 "Entrance To Or Exit To Service" 12 "Entrance To Or Exit Of A Car Park" 11 "Service Road Or Frontage Road" 10 "Slip Road per Ramp" 9 "Slip Road per Ramp On A Freeway Or Controlled Access Road" 8 "Parallel Road" 7 "Unused and Reserved 2" 6 "Unused and Reserved 1" 5 "Traffic Square per Special Traffic Figure" 4 "Roundabout Circle" 3 "Single Carriageway" 2 "Multiple Carriageway Or Multiply Digitized Road" 1 "Freeway Or Controlled Access Road That Is Not A Slip Road or Ramp" 0 "Unknown" ;
VAL_TABLE_ AdvDrAstMpSegEffSdLmtTp 7 "Not Applicable" 6 "Explicit Snow" 5 "Explicit Rain" 4 "Explicit Time Of Day" 3 "Explicit By Day" 2 "Explicit By Night" 1 "Explicit On Traffic Sign" 0 "Implicit" ;
VAL_TABLE_ AdvDrAstMpSegDivdRd 3 "Not Applicable" 2 "Unknown" 1 "Segment Is Part Of Divided Road" 0 "Segment Is Not Part Of Divided Road" ;
VAL_TABLE_ AdvDrAstMpSegCmplxInsct 3 "Not Applicable" 2 "Unknown" 1 "Segment Is Part Of Complex Intersection" 0 "Segment Is Not Part Of Complex Intersection" ;
VAL_TABLE_ AdvDrAstMpSegBrdg 3 "Not Applicable" 2 "Unknown" 1 "Segment Is Part Of Bridge" 0 "Segment Not Part Of Bridge" ;
VAL_TABLE_ AdvDrAstMpSegBldUpAra 3 "Not Applicable" 2 "Unknown" 1 "Segment Is Part Of Built Up Area" 0 "Segment Is Not Part Of Built Up Area" ;
VAL_TABLE_ AdvDrAstMpMtdtSpdUnt 1 "Miles Per Hour" 0 "Kilometers Per Hour" ;
VAL_TABLE_ AdvDrAstMpMtdtDrvSd 1 "Driving Side Right" 0 "Driving Side Left" ;
VAL_TABLE_ WSMR_WiFiAssnReq 3 "Unexpected Undefined Connection Behavior" 2 "Wi Fi association failed with available credentials" 1 "Failed to receive Wi Fi credentials after 255 attempts" 0 "SSID and Passphrase Request" ;
VAL_TABLE_ StrgColCommsFlt 2 "Disabled Communications DTC" 1 "No Communications Fault" 0 "Communications Fault" ;
VAL_TABLE_ CPMAPINFO4 1 "Hardware Or Software Error" 0 "No Hardware Or Software Error" ;
VAL_TABLE_ AdvDrvAstMpPrfShrt2Acur 3 "Accuracy Is Unknown" 2 "Lowest Accuracy" 1 "Medium Accuracy" 0 "Highest Accuracy" ;
VAL_TABLE_ InterLghtStat 1 "Interior Lights On" 0 "Interior Light Off" ;
VAL_TABLE_ VehLnStatConf 2 "High Confidence" 1 "Low Confidence" 0 "No Confidence" 3 "Very High Confidence" ;
VAL_TABLE_ VehLnStat 3 "Lane Change To Right" 2 "Lane Change To Left" 1 "Staying in Lane" 0 "Unknown" ;
VAL_TABLE_ HrznPrvdRstRq 1 "Reset Not Required" 0 "Reset Required" ;
VAL_TABLE_ ExptNxtTrnstnDirConf 3 "Very High Confidence" 2 "High Confidence" 1 "Low Confidence" 0 "No Confidence" ;
VAL_TABLE_ ExptNxtTrnstnDir 7 "Reserved4" 6 "Reserved3" 5 "Reserved2" 4 "Reserved1" 3 "Traversing Middle Transition" 2 "Traversing Next Transition Right" 1 "Traversing Next Transition Left" 0 "Unknown" ;
VAL_TABLE_ ADASISMsgTypRetrans 7 "GM System Specific" 6 "Meta Data" 5 "Profile Long" 4 "Profile Short" 3 "Stub" 2 "Segment" 1 "Position" 0 "Checksum" ;
VAL_TABLE_ NVSysStat 7 "Needs Headlights" 6 "Temporarily Unavailable" 5 "Not Dark" 4 "Needs Service" 3 "Active" 2 "Inactive" 1 "Initializing" 0 "Unknown" ;
VAL_TABLE_ NVSysPedWrnIndReq 3 "Unused & Reserved" 2 "Pedestrian Alert" 1 "Pedestrian Detected" 0 "None" ;
VAL_TABLE_ NVSysPedDetCstReq 2 "On" 1 "Off" 0 "No Value" ;
VAL_TABLE_ NVSysPedDetCsCrStVal 2 "On" 1 "Off" 0 "No Value" ;
VAL_TABLE_ FwVsnCinCoutPotT9Rev 2 "Right" 1 "Left" 0 "None" ;
VAL_TABLE_ FwVsnCinCoutPotT8Rev 2 "Right" 1 "Left" 0 "None" ;
VAL_TABLE_ FwVsnCinCoutPotT7Rev 2 "Right" 1 "Left" 0 "None" ;
VAL_TABLE_ FwVsnCinCoutPotT6Rev 2 "Right" 1 "Left" 0 "None" ;
VAL_TABLE_ FwVsnCinCoutPotT5Rev 2 "Right" 1 "Left" 0 "None" ;
VAL_TABLE_ FwVsnCinCoutPotT4Rev 2 "Right" 1 "Left" 0 "None" ;
VAL_TABLE_ FwVsnCinCoutPotT3Rev 2 "Right" 1 "Left" 0 "None" ;
VAL_TABLE_ FwVsnCinCoutPotT2Rev 2 "Right" 1 "Left" 0 "None" ;
VAL_TABLE_ FwVsnCinCoutPotT1Rev 2 "Right" 1 "Left" 0 "None" ;
VAL_TABLE_ FwVsnCinCoutPotT12Rev 2 "Right" 1 "Left" 0 "None" ;
VAL_TABLE_ FwVsnCinCoutPotT11Rev 2 "Right" 1 "Left" 0 "None" ;
VAL_TABLE_ FwVsnCinCoutPotT10Rev 2 "Right" 1 "Left" 0 "None" ;
VAL_TABLE_ GFHBObjDirTrk8 1 "Ahead Traffic" 0 "Incoming Traffic" ;
VAL_TABLE_ GFHBObjDirTrk7 1 "Ahead Traffic" 0 "Incoming Traffic" ;
VAL_TABLE_ GFHBObjDirTrk6 1 "Ahead Traffic" 0 "Incoming Traffic" ;
VAL_TABLE_ GFHBObjDirTrk5 1 "Ahead Traffic" 0 "Incoming Traffic" ;
VAL_TABLE_ GFHBObjDirTrk4 1 "Ahead Traffic" 0 "Incoming Traffic" ;
VAL_TABLE_ GFHBObjDirTrk3 1 "Ahead Traffic" 0 "Incoming Traffic" ;
VAL_TABLE_ GFHBObjDirTrk2 1 "Ahead Traffic" 0 "Incoming Traffic" ;
VAL_TABLE_ GFHBObjDirTrk1 1 "Ahead Traffic" 0 "Incoming Traffic" ;
VAL_TABLE_ GFHBFwVsnRelLaneTrk8 3 "Left Lane" 2 "Right Lane" 1 "Host Lane" 0 "Unknown" ;
VAL_TABLE_ GFHBFwVsnRelLaneTrk7 3 "Left Lane" 2 "Right Lane" 1 "Host Lane" 0 "Unknown" ;
VAL_TABLE_ GFHBFwVsnRelLaneTrk6 3 "Left Lane" 2 "Right Lane" 1 "Host Lane" 0 "Unknown" ;
VAL_TABLE_ GFHBFwVsnRelLaneTrk5 3 "Left Lane" 2 "Right Lane" 1 "Host Lane" 0 "Unknown" ;
VAL_TABLE_ GFHBFwVsnRelLaneTrk4 3 "Left Lane" 2 "Right Lane" 1 "Host Lane" 0 "Unknown" ;
VAL_TABLE_ GFHBFwVsnRelLaneTrk3 3 "Left Lane" 2 "Right Lane" 1 "Host Lane" 0 "Unknown" ;
VAL_TABLE_ GFHBFwVsnRelLaneTrk2 3 "Left Lane" 2 "Right Lane" 1 "Host Lane" 0 "Unknown" ;
VAL_TABLE_ GFHBFwVsnRelLaneTrk1 3 "Left Lane" 2 "Right Lane" 1 "Host Lane" 0 "Unknown" ;
VAL_TABLE_ GFHBFwVsnMesStatTrk8 3 "Measured this cycle" 2 "Latent track not detected this cycle" 1 "New Object" 0 "No Object" ;
VAL_TABLE_ GFHBFwVsnMesStatTrk7 3 "Measured this cycle" 2 "Latent track not detected this cycle" 1 "New Object" 0 "No Object" ;
VAL_TABLE_ GFHBFwVsnMesStatTrk6 3 "Measured this cycle" 2 "Latent track not detected this cycle" 1 "New Object" 0 "No Object" ;
VAL_TABLE_ GFHBFwVsnMesStatTrk5 3 "Measured this cycle" 2 "Latent track not detected this cycle" 1 "New Object" 0 "No Object" ;
VAL_TABLE_ GFHBFwVsnMesStatTrk4 3 "Measured this cycle" 2 "Latent track not detected this cycle" 1 "New Object" 0 "No Object" ;
VAL_TABLE_ GFHBFwVsnMesStatTrk3 3 "Measured this cycle" 2 "Latent track not detected this cycle" 1 "New Object" 0 "No Object" ;
VAL_TABLE_ GFHBFwVsnMesStatTrk2 3 "Measured this cycle" 2 "Latent track not detected this cycle" 1 "New Object" 0 "No Object" ;
VAL_TABLE_ GFHBFwVsnMesStatTrk1 3 "Measured this cycle" 2 "Latent track not detected this cycle" 1 "New Object" 0 "No Object" ;
VAL_TABLE_ GFHBFwVsnCnfdncTrk8 3 "Confident" 2 "Speculative" 1 "Highly Speculative" 0 "Invalid" ;
VAL_TABLE_ GFHBFwVsnCnfdncTrk7 3 "Confident" 2 "Speculative" 1 "Highly Speculative" 0 "Invalid" ;
VAL_TABLE_ GFHBFwVsnCnfdncTrk6 3 "Confident" 2 "Speculative" 1 "Highly Speculative" 0 "Invalid" ;
VAL_TABLE_ GFHBFwVsnCnfdncTrk5 3 "Confident" 2 "Speculative" 1 "Highly Speculative" 0 "Invalid" ;
VAL_TABLE_ GFHBFwVsnCnfdncTrk4 3 "Confident" 2 "Speculative" 1 "Highly Speculative" 0 "Invalid" ;
VAL_TABLE_ GFHBFwVsnCnfdncTrk3 3 "Confident" 2 "Speculative" 1 "Highly Speculative" 0 "Invalid" ;
VAL_TABLE_ GFHBFwVsnCnfdncTrk2 3 "Confident" 2 "Speculative" 1 "Highly Speculative" 0 "Invalid" ;
VAL_TABLE_ GFHBFwVsnCnfdncTrk1 0 "Invalid" 3 "Confident" 2 "Speculative" 1 "Highly Speculative" ;
VAL_TABLE_ GFHBFVsnObjTypTrkRev8 12 "Cluster Object" 11 "Child Close to Danger Zone" 10 "Pedestrian Moving Out of Danger Zone" 9 "Pedestrian Moving Into Danger Zone" 8 "Pedestrian Standing Outside Danger Zone" 7 "No Object Present" 6 "Fixed Roadside Object" 5 "Fixed Overhead Object" 4 "Pedestrian" 3 "Motorcycle/ Bicycle" 2 "Large Vehicle (Semi)" 1 "4 Wheel Vehicle (Car)" 0 "Unknown" ;
VAL_TABLE_ GFHBFVsnObjTypTrkRev7 12 "Cluster Object" 11 "Child Close to Danger Zone" 10 "Pedestrian Moving Out of Danger Zone" 9 "Pedestrian Moving Into Danger Zone" 8 "Pedestrian Standing Outside Danger Zone" 7 "No Object Present" 6 "Fixed Roadside Object" 5 "Fixed Overhead Object" 4 "Pedestrian" 3 "Motorcycle/ Bicycle" 2 "Large Vehicle (Semi)" 1 "4 Wheel Vehicle (Car)" 0 "Unknown" ;
VAL_TABLE_ GFHBFVsnObjTypTrkRev6 12 "Cluster Object" 11 "Child Close to Danger Zone" 10 "Pedestrian Moving Out of Danger Zone" 9 "Pedestrian Moving Into Danger Zone" 8 "Pedestrian Standing Outside Danger Zone" 7 "No Object Present" 6 "Fixed Roadside Object" 5 "Fixed Overhead Object" 4 "Pedestrian" 3 "Motorcycle/ Bicycle" 2 "Large Vehicle (Semi)" 1 "4 Wheel Vehicle (Car)" 0 "Unknown" ;
VAL_TABLE_ GFHBFVsnObjTypTrkRev5 12 "Cluster Object" 11 "Child Close to Danger Zone" 10 "Pedestrian Moving Out of Danger Zone" 9 "Pedestrian Moving Into Danger Zone" 8 "Pedestrian Standing Outside Danger Zone" 7 "No Object Present" 6 "Fixed Roadside Object" 5 "Fixed Overhead Object" 4 "Pedestrian" 3 "Motorcycle/ Bicycle" 2 "Large Vehicle (Semi)" 1 "4 Wheel Vehicle (Car)" 0 "Unknown" ;
VAL_TABLE_ GFHBFVsnObjTypTrkRev4 12 "Cluster Object" 11 "Child Close to Danger Zone" 10 "Pedestrian Moving Out of Danger Zone" 9 "Pedestrian Moving Into Danger Zone" 8 "Pedestrian Standing Outside Danger Zone" 7 "No Object Present" 6 "Fixed Roadside Object" 5 "Fixed Overhead Object" 4 "Pedestrian" 3 "Motorcycle/ Bicycle" 2 "Large Vehicle (Semi)" 1 "4 Wheel Vehicle (Car)" 0 "Unknown" ;
VAL_TABLE_ GFHBFVsnObjTypTrkRev3 12 "Cluster Object" 11 "Child Close to Danger Zone" 10 "Pedestrian Moving Out of Danger Zone" 9 "Pedestrian Moving Into Danger Zone" 8 "Pedestrian Standing Outside Danger Zone" 7 "No Object Present" 6 "Fixed Roadside Object" 5 "Fixed Overhead Object" 4 "Pedestrian" 3 "Motorcycle/ Bicycle" 2 "Large Vehicle (Semi)" 1 "4 Wheel Vehicle (Car)" 0 "Unknown" ;
VAL_TABLE_ GFHBFVsnObjTypTrkRev2 12 "Cluster Object" 11 "Child Close to Danger Zone" 10 "Pedestrian Moving Out of Danger Zone" 9 "Pedestrian Moving Into Danger Zone" 8 "Pedestrian Standing Outside Danger Zone" 7 "No Object Present" 6 "Fixed Roadside Object" 5 "Fixed Overhead Object" 4 "Pedestrian" 3 "Motorcycle/ Bicycle" 2 "Large Vehicle (Semi)" 1 "4 Wheel Vehicle (Car)" 0 "Unknown" ;
VAL_TABLE_ GFHBFVsnObjTypTrkRev1 12 "Cluster Object" 11 "Child Close to Danger Zone" 10 "Pedestrian Moving Out of Danger Zone" 9 "Pedestrian Moving Into Danger Zone" 8 "Pedestrian Standing Outside Danger Zone" 7 "No Object Present" 6 "Fixed Roadside Object" 5 "Fixed Overhead Object" 4 "Pedestrian" 3 "Motorcycle/ Bicycle" 2 "Large Vehicle (Semi)" 1 "4 Wheel Vehicle (Car" 0 "Unknown" ;
VAL_TABLE_ CRL_Cnfdnc 7 "Reserved4" 6 "Reserved3" 5 "Reserved2" 4 "Reserved1" 3 "Best" 2 "Marking Present" 1 "Weak Marking" 0 "No Lane" ;
VAL_TABLE_ CLL_Cnfdnc 7 "Reserved4" 6 "Reserved3" 5 "Reserved2" 4 "Reserved1" 3 "Best" 2 "Marking Present" 1 "Weak Marking" 0 "No Lane" ;
VAL_TABLE_ VBBrkCtrlSt 4 "Release Control" 3 "Hold Vehicle" 2 "Apply Brake" 1 "Decrease Torque" 0 "No Action" ;
VAL_TABLE_ ObstacleType 6 "NO_OBJECT" 5 "OBJ_GUARDRAIL" 4 "OBJ_TUNNEL " 3 "OBJ_TRAFFIC_SIGN" 2 "OBJ_VEHICLE" 1 "OBJ_BRIDGE " 0 "OBJ_UNKNOWN" ;
VAL_TABLE_ VpathMode 2 "Mid Hi Speed" 1 "Low Speed" 0 "Disabled" ;
VAL_TABLE_ LaneChngStatus 2 "Lane Change Right" 1 "Lane Change Left" 0 "Idle" ;
VAL_TABLE_ TravelDirection 3 "Other (excessive side slip)" 2 "reverse / stopped in rvrs gear" 1 "Forward / stopped in frwd gear" 0 "Unknown" ;
VAL_TABLE_ TrueOrFalse 1 "true" 0 "false" ;
VAL_TABLE_ ModeCommand 5 "Sensing with Reduced Power" 4 "Undefined" 3 "Radio Silent" 2 "Sensing" 1 "Not Sensing" 0 "Undefined" ;
VAL_TABLE_ LaneSnsLLnPosValid 1 "Invalid" 0 "Valid" ;
VAL_TABLE_ LnSnsRLnPosValid 1 "Invalid" 0 "Valid" ;
VAL_TABLE_ Elevation 3 "Low " 2 "mid (reserved)" 1 "high " 0 "Unknown" ;
VAL_TABLE_ ModeCommandFdbk 5 "Sensing with reduced power" 4 "Undefined" 3 "Radio Silent" 2 "Sensing" 1 "Not Sensing" 0 "Undefined" ;
VAL_TABLE_ relativeLane 3 "Left Lane" 2 "Right Lane" 1 "Host Lane" 0 "Unknown" ;
VAL_TABLE_ RoadTypeInfo 5 "Constiction Zone Exit" 4 "Construction Zone Entry" 3 "Highway" 2 "Secondary Road" 1 "City" 0 "Unknown" ;
VAL_TABLE_ ObjectLossInfo 2 "elevation conditions" 1 "tight curve" 0 "not lost" ;
VAL_TABLE_ MeasurementStatus 3 "Measured this cycle" 2 "Latent track not detctd this cyc" 1 "New Object" 0 "No Object" ;
VAL_TABLE_ ObjectType 7 "no object present" 6 "fixed roadside object" 5 "fixed overhead object" 4 "pedestrian" 3 "motocycle  / bicycle" 2 "Large vehicle (semi)" 1 "4 Wheel Vehicle (car, small trk)" 0 "Unknown" ;
VAL_TABLE_ Confidence 3 "confident" 2 "speculative" 1 "highly speculative" 0 "invalid" ;
VAL_TABLE_ DynamicProp 4 "Moving in opposite direction" 3 "Moving in same direction as host" 2 "Has moved but currently stopped" 1 "Has never moved" 0 "Unknown" ;
VAL_TABLE_ DrvWndPosSt 6 "Fully Opened" 5 "Open More Than C" 4 "Position C" 3 "Position B" 2 "Position A" 1 "Open Less Than A" 0 "Fully Closed" ;
VAL_TABLE_ VehMovSta 4 "Invalid" 3 "Reverse" 2 "Forward" 1 "Neutral" 0 "Parked" ;
VAL_TABLE_ OtsdAmbtLtLvlStat 2 "Day" 1 "Night" 0 "Unknown" ;
VAL_TABLE_ RtTrnLmpAtv 2 "On with telltale" 1 "On without telltale" 0 "Off" ;
VAL_TABLE_ LftTrnLmpAtv 2 "On with telltale" 1 "On without telltale" 0 "Off" ;
VAL_TABLE_ HdlmpBmSelectStat 2 "High Beams" 1 "Low Beams" 0 "Unknown" ;
VAL_TABLE_ DTCI_DTCFaultType 3 "Type C" 2 "Type B" 1 "Type A" 0 "Not Supported" ;
VAL_TABLE_ TrnsShftLvrPos 13 "Forward Range J" 12 "Forward Range I" 15 "Lever Position Unknown" 11 "Forward Range H" 10 "Forward Range G" 9 "Forward Range F" 8 "Forward Range E" 7 "Forward Range D" 6 "Forward Range C" 5 "Forward Range B" 4 "Forward Range A" 3 "Neutral Range" 2 "Reverse Range" 1 "Park Range" 0 "Between Ranges" ;
VAL_TABLE_ SysPwrMd 3 "Crank Request" 2 "Run" 1 "Accessory" 0 "Off" ;
VAL_TABLE_ ValidityStates 1 "Invalid" 0 "Valid" ;

CM_ SG_ 970 Lkas_Action "only vals 4, 5, 8, 9 seem to work. 4 and 5 are a bit smoother" ;
